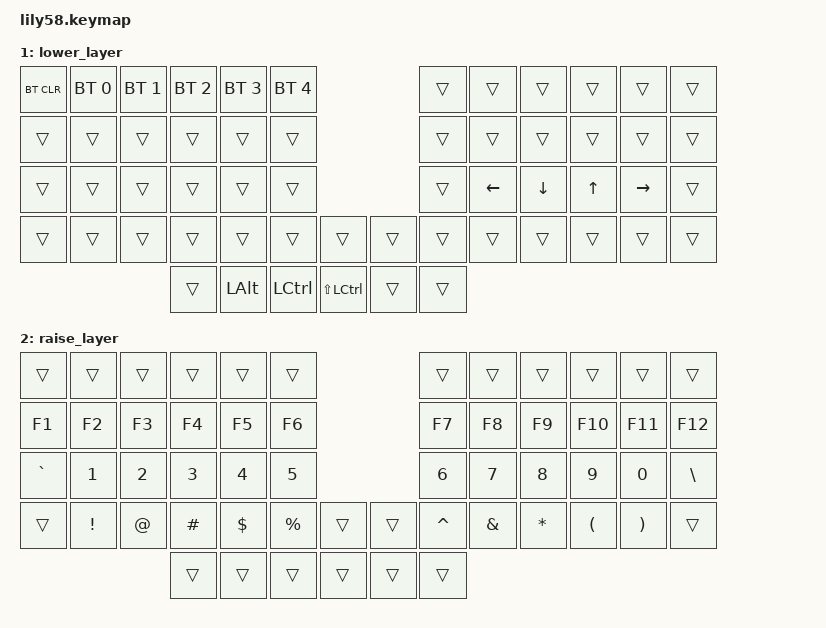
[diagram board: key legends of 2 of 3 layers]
/*
 * Copyright (c) 2020 The ZMK Contributors
 *
 * SPDX-License-Identifier: MIT
 */

#include <behaviors.dtsi>
#include <dt-bindings/zmk/bt.h>
#include <dt-bindings/zmk/keys.h>

/ {
    keymap {
        compatible = "zmk,keymap";

        default_layer {
            // ------------------------------------------------------------------------------------------------------------
            // |  ESC |  1  |  2  |  3   |  4   |  5   |                   |  6   |  7    |  8    |  9   |   0   |   GUI |
            // |   /  |  Q  |  W  |  F   |  P   |  B   |                   |  J   |  L    |  U    |  Y   |   Z   |   '   |
            // | SHIFT|  A  |  R  |  S   |  T   |  G   |                   |  M   |  N    |  E    |  I   |   O   | SHIFT |
            // |   -  |  X  |  C  |  D   |  V   |  ;   |   "["  |  |  "]"  |  +   |  K    |  H    |  ,   |   .   |   `   |
            //                    |LOWER | ALT  | TAB  |  SPACE |  | BSPC  | ENTER| CTRL  | HIGHER|

            bindings = <
&kp ESC    &kp N1  &kp N2  &kp N3    &kp N4    &kp N5                              &kp N6         &kp N7  &kp N8  &kp N9     &kp N0   &kp BSLH
&kp FSLH   &kp Q   &kp W   &kp F     &kp P     &kp B                               &kp J          &kp L   &kp U   &kp Y      &kp Z    &kp SQT
&kp TAB    &kp A   &kp R   &kp S     &kp T     &kp G                               &kp M          &kp N   &kp E   &kp I      &kp O    &kp ENTER
&kp MINUS  &kp X   &kp C   &kp D     &kp V     &kp SEMI   &kp LBKT     &kp RBKT    &kp PLUS       &kp K   &kp H   &kp COMMA  &kp DOT  &kp GRAVE
                           &kp LWIN  &kp LALT  &kp LCTRL  &kp SPACE    &kp LSHIFT  &kp BACKSPACE  &mo 1   &mo 2
            >;
        };

        lower_layer {
            // ------------------------------------------------------------------------------------------------------------
            // |       |     |     |      |      |      |                   |      |       |       |      |       |       |
            // |       |     |     |      |      |      |                   |      |       |       |      |       |       |
            // |       |     |     |      |      |      |                   |      |   <-  |   v   |  ^   |   ->  |       |
            // |       |     |     |      |      |      |                   |      |       |       |      |       |       |
            //                     |      |      |      |        |  | DELETE|      |       |       |

            bindings = <
&bt BT_CLR  &bt BT_SEL 0  &bt BT_SEL 1  &bt BT_SEL 2  &bt BT_SEL 3  &bt BT_SEL 4                           &trans  &trans    &trans    &trans  &trans     &trans
&trans      &trans        &trans        &trans        &trans        &trans                                 &trans  &trans    &trans    &trans  &trans     &trans
&trans      &trans        &trans        &trans        &trans        &trans                                 &trans  &kp LEFT  &kp DOWN  &kp UP  &kp RIGHT  &trans
&trans      &trans        &trans        &trans        &trans        &trans        &trans           &trans  &trans  &trans    &trans    &trans  &trans     &trans
                                        &trans        &kp LEFT_ALT  &kp LCTRL     &kp LS(LCTRL)    &trans  &trans
            >;
        };

        raise_layer {
            // ------------------------------------------------------------------------------------------------------------
            // |       |     |     |      |      |      |                   |      |       |       |      |       |       |
            // |  F1   |  F2 |  F3 |  F4  |  F5  |  F6  |                   |  F7  |  F8   |  F9   |  F10 |  F11  |  F12  |
            // |       |  1  |  2  |  3   |  4   |  5   |                   |  6   |   7   |   8   |  9   |   0   | BSLH  |
            // |       |     |     |      |      |      |                   |      |       |       |      |       |       |
            //                     |      |      |      |        |  |       |      |       |       |

            bindings = <
&trans     &trans    &trans  &trans    &trans      &trans                       &trans     &trans    &trans    &trans    &trans    &trans
&kp F1     &kp F2    &kp F3  &kp F4    &kp F5      &kp F6                       &kp F7     &kp F8    &kp F9    &kp F10   &kp F11   &kp F12
&kp GRAVE  &kp N1    &kp N2  &kp N3    &kp N4      &kp N5                       &kp N6     &kp N7    &kp N8    &kp N9    &kp N0    &kp BSLH
&trans     &kp EXCL  &kp AT  &kp HASH  &kp DOLLAR  &kp PRCNT  &trans    &trans  &kp CARET  &kp AMPS  &kp STAR  &kp LPAR  &kp RPAR  &trans
                             &trans    &trans      &trans     &trans    &trans  &trans
            >;
        };
    };
};
